# K32W061 register map
Vendor: nxp.com; File version: 1.0
CPU: CM4 r0p1, little endian, MPU, no FPU, VTOR, 3 interrupt priority bits
Registers are 32-bit, read-write, reset 0x0 unless marked. A register's access mark holds for its fields unless they carry their own. Offsets are from the block's base; [hi:lo] are bit positions; {n}, {i} and the like mark numbered series.

## SHA0 — This is the description of component hash It is AES 128-192-256 with GCM mode. More details will follow.
Base 0x4008F000
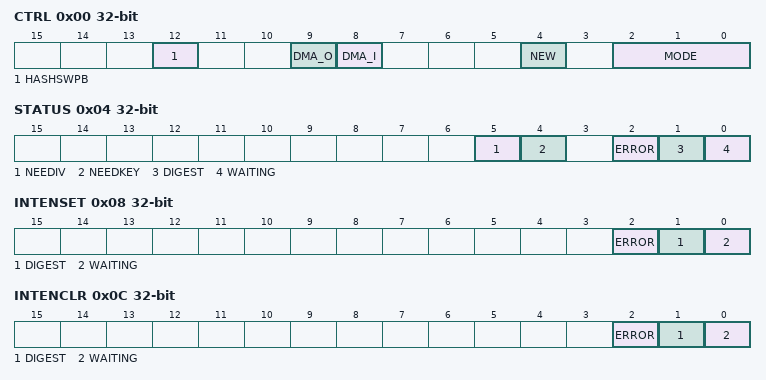
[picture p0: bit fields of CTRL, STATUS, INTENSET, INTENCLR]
0x00 CTRL (reset mask 0x1307) — Control register
  [12] HASHSWPB — If 1, will swap bytes in the word for SHA hashing. The default is byte order (so LSB is first byte) but this allows swapping to MSB is first.
  [9] DMA_O — Written to 1 to use DMA to drain the digest/output. If both DMA_I and DMA_O are set, the DMA has to know to switch direction and the locations. If written to 0 the DMA is not used and the processor has to read the digest/output in response to the DIGEST interrupt.
  [8] DMA_I — Written with 1 to use DMA to fill INDATA. For Hash, will request from DMA for 16 words and then will process the Hash. Normal model is that the DMA interrupts the processor when its length expires.
  [4] NEW wo — Written with 1 when starting a new Hash. It self clears. Note that the WAITING Status bit will clear for a cycle during the initialization from New=1. Digest/Result is initialized when New is set to 1.
  [2:0] MODE — Operational mode: 0: Disabled; 1: SHA1; 2: SHA2-256; 3: SHA2-512; 4-7: Not valid
0x04 STATUS ro — Status Regsiter
  [5] NEEDIV — Indicates the block wants an IV/NONE to be written in (set along with WAITING). 0: no IV is needed, either because written already or because not needed. 1: IV needed and INDATA will be accepted as IV.
  [4] NEEDKEY — Indicates the block wants the key to be written in (set along with WAITING). 0: no key is needed and writes will not be treated as Key. 1: key is needed and INDATA will be accepted as key. Will also set WAITING.
  [2] ERROR — If 1, an error occurred. For normal uses, this is due to an attempted overrun: INDATA was written when it was not appropriate. Write 1 to clear.
  [1] DIGEST — If 1 then a DIGEST is ready and waiting and there is no active next block already started. This is cleared when any data is written, when New is written, or when the block is disabled.
  [0] WAITING — Waiting Status 0: Not waiting for data may be disabled or may be busy. Note that for cryptographic uses, this is not set if IsLast is set nor will it set until at least 1 word is read of the output. 1: Waiting for data to be written in (16 words)
0x08 INTENSET — Interrupt Enable and Interrupt enable set function
  [2] ERROR — 0: Will not interrupt on Error. 1: Will interrupt on Error. Write 1 to set this bit.
  [1] DIGEST — 0: Will not interrupt when Digest is ready. 1: Will interrupt when Digest is ready. Write 1 to set this bit.
  [0] WAITING — 0: Will not interrupt when waiting. 1: Will interrupt when waiting. Write 1 to set this bit.
0x0C INTENCLR reset not defined — Interrupt Clear Register
  [2] ERROR wo — Write 1 to clear correspnding bit in INTENSET.
  [1] DIGEST wo — Write 1 to clear correspnding bit in INTENSET.
  [0] WAITING wo — Write 1 to clear correspnding bit in INTENSET.
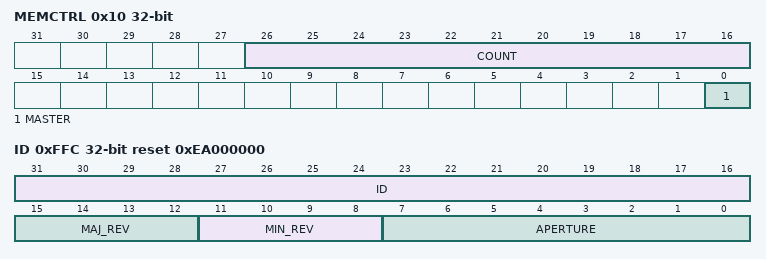
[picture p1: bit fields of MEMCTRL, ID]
0x10 MEMCTRL — Setup Master to access memory
  [26:16] COUNT — Number of 512-bit blocks to copy starting at MEMADDR. This register will decrement after each block is copied, ending in 0. For Hash, the DIGEST interrupt will occur when it reaches 0. If a bus error occurs, it will stop with this field set to the block that failed
  [0] MASTER — Enables Mastering. 0: Mastering is not used and the normal DMA or Interrupt based model is used with INDATA. 1: Mastering is enabled and DMA and INDATA should not be used.
0x14 MEMADDR — Address to start memory access from
  [31:0] BASEADDR — This field indicates the base address in Internal Flash, SRAM0, SRAMX, or SPIFI to start copying from.
{0x20+4i} INDATA[{i}] (i=0..7) — Input Data register
  [31:0] DATA — In this field the next word is written in little-endian format.
{0x40+4i} DIGEST[{i}] (i=0..7) ro — DIGEST or OUTD0, 5 or 8 bytes of output data, depending upon mode
  [31:0] DIGEST — This field contains one word of the Digest.
0x90 MASK
0xFFC ID ro reset 0xEA000000 — IP identifier
  [31:16] ID — Identifier. This is the unique identifier of the module
  [15:12] MAJ_REV — Major revision i.e. implies software modifications
  [11:8] MIN_REV — Minor revision i.e. with no software consequences
  [7:0] APERTURE — Aperture i.e. number minus 1 of consecutive packets 4 Kbytes reserved for this IP
